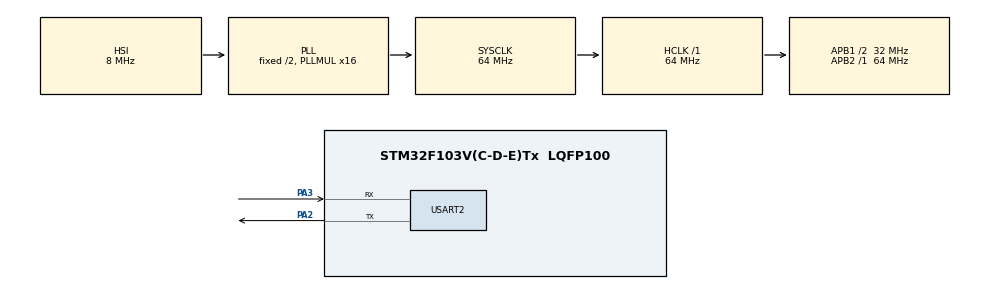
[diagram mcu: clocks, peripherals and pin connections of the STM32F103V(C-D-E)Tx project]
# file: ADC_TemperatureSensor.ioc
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ADC1.Channel-0\#ChannelRegularConversion=ADC_CHANNEL_TEMPSENSOR
ADC1.ContinuousConvMode=ENABLE
ADC1.NbrOfConversionFlag=1
ADC1.Rank-0\#ChannelRegularConversion=1
ADC1.SamplingTime-0\#ChannelRegularConversion=ADC_SAMPLETIME_13CYCLES_5
ADC1.master=1
Mcu.Family=STM32F1
Mcu.Name=STM32F103V(C-D-E)Tx
Mcu.Package=LQFP100
NVIC.PriorityGroup=NVIC_PRIORITYGROUP_4
NVIC.USART2_IRQn=true\:0\:0\:false\:false\:true\:true\:true
PA2.Mode=Asynchronous
PA2.Signal=USART2_TX
PA3.Mode=Asynchronous
PA3.Signal=USART2_RX
ProjectManager.HeapSize=0x200
ProjectManager.StackSize=0x400
ProjectManager.TargetToolchain=STM32CubeIDE
RCC.ADCPresc=RCC_ADCPCLK2_DIV8
RCC.AHBFreq_Value=64000000
RCC.APB1CLKDivider=RCC_HCLK_DIV2
RCC.APB1Freq_Value=32000000
RCC.APB1TimFreq_Value=64000000
RCC.APB2Freq_Value=64000000
RCC.APB2TimFreq_Value=64000000
RCC.HCLKFreq_Value=64000000
RCC.PLLMUL=RCC_PLL_MUL16
RCC.SYSCLKFreq_VALUE=64000000
RCC.SYSCLKSource=RCC_SYSCLKSOURCE_PLLCLK
RCC.USBFreq_Value=64000000
USART2.VirtualMode=VM_ASYNC
VP_ADC1_TempSens_Input.Mode=IN-TempSens
VP_SYS_VS_ND.Mode=No_Debug
board=custom

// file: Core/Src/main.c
/* USER CODE BEGIN Header */
/**
  ******************************************************************************
  * @file           : main.c
  * @brief          : Main program body
  ******************************************************************************
  * @attention
  *
  * <h2><center>&copy; Copyright (c) 2020 STMicroelectronics.
  * All rights reserved.</center></h2>
  *
  * This software component is licensed by ST under BSD 3-Clause license,
  * the "License"; You may not use this file except in compliance with the
  * License. You may obtain a copy of the License at:
  *                        opensource.org/licenses/BSD-3-Clause
  *
  ******************************************************************************
  */
/* USER CODE END Header */

#include "main.h"

/* USER CODE BEGIN Includes */
#include <stdio.h>
/* USER CODE END Includes */

ADC_HandleTypeDef hadc1;

UART_HandleTypeDef huart2;

/* USER CODE BEGIN PV */
const float AVG_SLOPE = 4.3E-03;			// slope (gradient) of temperature line function
const float V25 = 1.43;						// sensor's voltage at 25도 [V]
const float ADC_TO_VOLT = 3.3 / 4096;		// conversion coefficient of digital value to volt
/* USER CODE END PV */

void SystemClock_Config(void);
static void MX_GPIO_Init(void);
static void MX_ADC1_Init(void);
static void MX_USART2_UART_Init(void);

/* USER CODE BEGIN 0 */
#ifdef __GNUC__
/* With GCC, small printf (option LD Linker->Libraries->Small printf
   set to 'Yes') calls __io_putchar() */
#define PUTCHAR_PROTOTYPE int __io_putchar(int ch)
#else
#define PUTCHAR_PROTOTYPE int fputc(int ch, FILE *f)
#endif /* __GNUC__ */

/**
  * @brief  Retargets the C library printf function to the USART.
  * @param  None
  * @retval None
  */
PUTCHAR_PROTOTYPE
{
  /* Place your implementation of fputc here */
  /* e.g. write a character to the USART1 and Loop until the end of transmission */
  if (ch == '\n')
    HAL_UART_Transmit (&huart2, (uint8_t*) "\r", 1, 0xFFFF);
  HAL_UART_Transmit (&huart2, (uint8_t*) &ch, 1, 0xFFFF);

  return ch;
}
/* USER CODE END 0 */

int main(void)
{

  /* MCU Configuration--------------------------------------------------------*/

  /* Reset of all peripherals, Initializes the Flash interface and the Systick. */
  HAL_Init();

  /* Configure the system clock */
  SystemClock_Config();

  /* Initialize all configured peripherals */
  MX_GPIO_Init();
  MX_ADC1_Init();
  MX_USART2_UART_Init();

  /* Infinite loop */
  /* USER CODE BEGIN WHILE */

  // start calibration
  if(HAL_ADCEx_Calibration_Start(&hadc1) != HAL_OK)
  {
	  Error_Handler();
  }

  // start the conversion process
  if(HAL_ADC_Start(&hadc1) != HAL_OK)
  {
	  Error_Handler();
  }

  uint16_t adc1;

  float vSense;		// sensor's output voltage [V]
  float temp;		// sensor's temperature [도]

  while (1)
  {
	  HAL_ADC_PollForConversion(&hadc1, 100);	// AD변환 100ms 대기
	  adc1 = HAL_ADC_GetValue(&hadc1);	// 결과값 읽기
//	  printf("ADC1_temperature : %d \n", adc1);

	  vSense = adc1 * ADC_TO_VOLT;
	  temp = (V25 - vSense) / AVG_SLOPE + 25.0;
	  printf("temperature: %d, %f \n", adc1, temp);
    /* USER CODE END WHILE */

    /* USER CODE BEGIN 3 */
	  HAL_Delay(100);
  }
  /* USER CODE END 3 */
}

void SystemClock_Config(void)
{
  RCC_OscInitTypeDef RCC_OscInitStruct = {0};
  RCC_ClkInitTypeDef RCC_ClkInitStruct = {0};
  RCC_PeriphCLKInitTypeDef PeriphClkInit = {0};

  /** Initializes the CPU, AHB and APB busses clocks
  */
  RCC_OscInitStruct.OscillatorType = RCC_OSCILLATORTYPE_HSI;
  RCC_OscInitStruct.HSIState = RCC_HSI_ON;
  RCC_OscInitStruct.HSICalibrationValue = RCC_HSICALIBRATION_DEFAULT;
  RCC_OscInitStruct.PLL.PLLState = RCC_PLL_ON;
  RCC_OscInitStruct.PLL.PLLSource = RCC_PLLSOURCE_HSI_DIV2;
  RCC_OscInitStruct.PLL.PLLMUL = RCC_PLL_MUL16;
  if (HAL_RCC_OscConfig(&RCC_OscInitStruct) != HAL_OK)
  {
    Error_Handler();
  }
  /** Initializes the CPU, AHB and APB busses clocks
  */
  RCC_ClkInitStruct.ClockType = RCC_CLOCKTYPE_HCLK|RCC_CLOCKTYPE_SYSCLK
                              |RCC_CLOCKTYPE_PCLK1|RCC_CLOCKTYPE_PCLK2;
  RCC_ClkInitStruct.SYSCLKSource = RCC_SYSCLKSOURCE_PLLCLK;
  RCC_ClkInitStruct.AHBCLKDivider = RCC_SYSCLK_DIV1;
  RCC_ClkInitStruct.APB1CLKDivider = RCC_HCLK_DIV2;
  RCC_ClkInitStruct.APB2CLKDivider = RCC_HCLK_DIV1;

  if (HAL_RCC_ClockConfig(&RCC_ClkInitStruct, FLASH_LATENCY_2) != HAL_OK)
  {
    Error_Handler();
  }
  PeriphClkInit.PeriphClockSelection = RCC_PERIPHCLK_ADC;
  PeriphClkInit.AdcClockSelection = RCC_ADCPCLK2_DIV8;
  if (HAL_RCCEx_PeriphCLKConfig(&PeriphClkInit) != HAL_OK)
  {
    Error_Handler();
  }
}

static void MX_ADC1_Init(void)
{

  ADC_ChannelConfTypeDef sConfig = {0};

  /** Common config
  */
  hadc1.Instance = ADC1;
  hadc1.Init.ScanConvMode = ADC_SCAN_DISABLE;
  hadc1.Init.ContinuousConvMode = ENABLE;
  hadc1.Init.DiscontinuousConvMode = DISABLE;
  hadc1.Init.ExternalTrigConv = ADC_SOFTWARE_START;
  hadc1.Init.DataAlign = ADC_DATAALIGN_RIGHT;
  hadc1.Init.NbrOfConversion = 1;
  if (HAL_ADC_Init(&hadc1) != HAL_OK)
  {
    Error_Handler();
  }
  /** Configure Regular Channel
  */
  sConfig.Channel = ADC_CHANNEL_TEMPSENSOR;
  sConfig.Rank = ADC_REGULAR_RANK_1;
  sConfig.SamplingTime = ADC_SAMPLETIME_13CYCLES_5;
  if (HAL_ADC_ConfigChannel(&hadc1, &sConfig) != HAL_OK)
  {
    Error_Handler();
  }

}

static void MX_USART2_UART_Init(void)
{

  huart2.Instance = USART2;
  huart2.Init.BaudRate = 115200;
  huart2.Init.WordLength = UART_WORDLENGTH_8B;
  huart2.Init.StopBits = UART_STOPBITS_1;
  huart2.Init.Parity = UART_PARITY_NONE;
  huart2.Init.Mode = UART_MODE_TX_RX;
  huart2.Init.HwFlowCtl = UART_HWCONTROL_NONE;
  huart2.Init.OverSampling = UART_OVERSAMPLING_16;
  if (HAL_UART_Init(&huart2) != HAL_OK)
  {
    Error_Handler();
  }

}

static void MX_GPIO_Init(void)
{

  /* GPIO Ports Clock Enable */
  __HAL_RCC_GPIOA_CLK_ENABLE();

}

void Error_Handler(void)
{
}

/************************ (C) COPYRIGHT STMicroelectronics *****END OF FILE****/
